# AVR64EA48 register map
Vendor: Atmel; File version: 1.0
CPU: other r0p0, little endian, no MPU, no FPU, 4 interrupt priority bits
Registers are 8-bit, read-write, reset 0x0 unless marked. A register's access mark holds for its fields unless they carry their own. Offsets are from the block's base; [hi:lo] are bit positions.

## PORTMUX — Port Multiplexer
Base 0x008005E0
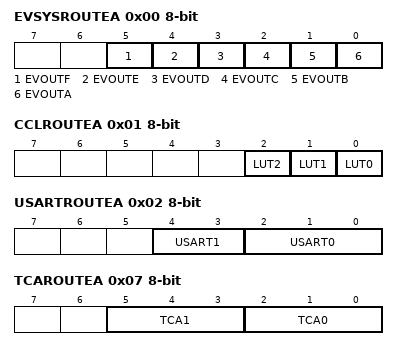
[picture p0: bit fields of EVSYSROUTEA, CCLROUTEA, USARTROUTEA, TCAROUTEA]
0x00 EVSYSROUTEA
  [5] EVOUTF — Event Output F
    0=DEFAULT (EVOUTF: PF2); 1=ALT1 (EVOUTF: PF7)
  [4] EVOUTE — Event Output E
    0=DEFAULT (EVOUTE: PE2)
  [3] EVOUTD — Event Output D
    0=DEFAULT (EVOUTD: PD2); 1=ALT1 (EVOUTD: PD7)
  [2] EVOUTC — Event Output C
    0=DEFAULT (EVOUTC: PC2); 1=ALT1 (EVOUTC: PC7)
  [1] EVOUTB — Event Output B
    0=DEFAULT (EVOUTB: PB2)
  [0] EVOUTA — Event Output A
    0=DEFAULT (EVOUTA: PA2); 1=ALT1 (EVOUTA: PA7)
0x01 CCLROUTEA
  [2] LUT2 — CCL Look-Up Table 2 Signals
    0=DEFAULT (In: PD0, PD1, PD2, Out: PD3); 1=ALT1 (In: PD0, PD1, PD2, Out: PD6)
  [1] LUT1 — CCL Look-Up Table 1 Signals
    0=DEFAULT (In: PC0, PC1, PC2, Out: PC3); 1=ALT1 (In: PC0, PC1, PC2, Out: PC6)
  [0] LUT0 — CCL Look-Up Table 0 Signals
    0=DEFAULT (In: PA0, PA1, PA2, Out: PA3); 1=ALT1 (In: PA0, PA1, PA2, Out: PA6)
0x02 USARTROUTEA
  [4:3] USART1 — USART1 Routing
    0=DEFAULT (TxD: PC0, RxD: PC1, XCK: PC2, XDIR: PC3); 1=ALT1 (TxD: PC4, RxD: PC5, XCK: PC6, XDIR: PC7); 2=ALT2 (TxD: PD6, RxD: PD7, XCK: -, XDIR: -); 3=NONE (Not connected to any pins)
  [2:0] USART0 — USART0 Routing
    0=DEFAULT (TxD: PA0, RxD: PA1, XCK: PA2, XDIR: PA3); 1=ALT1 (TxD: PA4, RxD: PA5, XCK: PA6, XDIR: PA7); 2=ALT2 (TxD: PA2, RxD: PA3, XCK: -, XDIR: -); 3=ALT3 (TxD: PD4, RxD: PD5, XCK: PD6, XDIR: PD7); 4=ALT4 (TxD: PC1, RxD: PC2, XCK: PC3, XDIR: -); 5=NONE (Not connected to any pins)
0x03 USARTROUTEB
  [1:0] USART2 — USART2 Routing
    0=DEFAULT (TxD: PF0, RxD: PF1, XCK: PF2, XDIR: PF3); 1=ALT1 (TxD: PF4, RxD: PF5, XCK: - , XDIR: -); 3=NONE (Not connected to any pins)
0x05 SPIROUTEA
  [2:0] SPI0 — SPI0 Signals
    0=DEFAULT (MOSI: PA4, MISO: PA5, SCK: PA6, SS: PA7); 1=ALT1 (MOSI: PE0, MISO: PE1, SCK: PE2, SS: PE3); 3=ALT3 (MOSI: PA0, MISO: PA1, SCK: PC0, SS: PC1); 4=ALT4 (MOSI: PD4, MISO: PD5, SCK: PD6, SS: PD7); 5=ALT5 (MOSI: PC0, MISO: PC1, SCK: PC2, SS: PC3); 6=ALT6 (MOSI: PC1, MISO: PC2, SCK: PC3, SS: PF7); 7=NONE (Not connected to any pins, SS set to 1)
0x06 TWIROUTEA
  [1:0] TWI0 — TWI0 Signals
    0=DEFAULT (SDA: PA2, SCL: PA3. Dual mode: SDA: PC2, SCL: PC3); 1=ALT1 (SDA: PA2, SCL: PA3. Dual mode: SDA: PC6, SCL: PC7); 2=ALT2 (SDA: PC2, SCL: PC3. Dual mode: SDA: PC6, SCL: PC7); 3=ALT3 (SDA: PA0, SCL: PA1. Dual mode: SDA: PC2, SCL: PC3)
0x07 TCAROUTEA
  [5:3] TCA1 — TCA1 Signals
    0=PORTB (WOn: PB0, PB1, PB2, PB3, PB4, PB5); 1=PORTC (WOn: PC4, PC5, PC6, -, -, -); 4=PORTA (WOn: PA4, PA5, PA6, -, -, -); 5=PORTD (WOn: PD4, PD5, PD6, -, -, -)
  [2:0] TCA0 — TCA0 Signals
    0=PORTA (WOn: PA0, PA1, PA2, PA3, PA4, PA5); 1=PORTB (WOn: PB0, PB1, PB2, PB3, PB4, PB5); 2=PORTC (WOn: PC0, PC1, PC2, PC3, PC4, PC5); 3=PORTD (WOn: PD0, PD1, PD2, PD3, PD4, PD5); 4=PORTE (WOn: PE0, PE1, PE2, PE3, -, -); 5=PORTF (WOn: PF0, PF1, PF2, PF3, PF4, PF5)
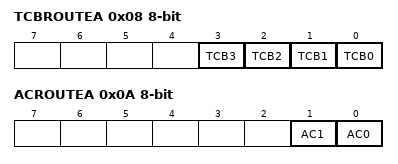
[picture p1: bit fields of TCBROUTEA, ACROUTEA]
0x08 TCBROUTEA
  [3] TCB3 — TCB3 Output
    0=DEFAULT (WO: PB5); 1=ALT1 (WO: PC1)
  [2] TCB2 — TCB2 Output
    0=DEFAULT (WO: PC0); 1=ALT1 (WO: PB4)
  [1] TCB1 — TCB1 Output
    0=DEFAULT (WO: PA3); 1=ALT1 (WO: PF5)
  [0] TCB0 — TCB0 Output
    0=DEFAULT (WO: PA2); 1=ALT1 (WO: PF4)
0x0A ACROUTEA
  [1] AC1 — Analog Comparator 1 Output
    0=DEFAULT (OUT: PA7); 1=ALT1 (OUT: PC6)
  [0] AC0 — Analog Comparator 0 Output
    0=DEFAULT (OUT: PA7); 1=ALT1 (OUT: PC6)

## RSTCTRL — Reset controller
Base 0x00800040
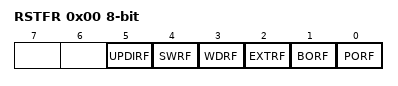
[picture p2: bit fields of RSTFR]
0x00 RSTFR — Reset Flags
  [5] UPDIRF — UPDI Reset flag
  [4] SWRF — Software Reset flag
  [3] WDRF — Watch dog Reset flag
  [2] EXTRF — External Reset flag
  [1] BORF — Brown out detector Reset flag
  [0] PORF — Power on Reset flag
0x01 SWRR — Software Reset
  [0] SWRE — Software Reset Enable
